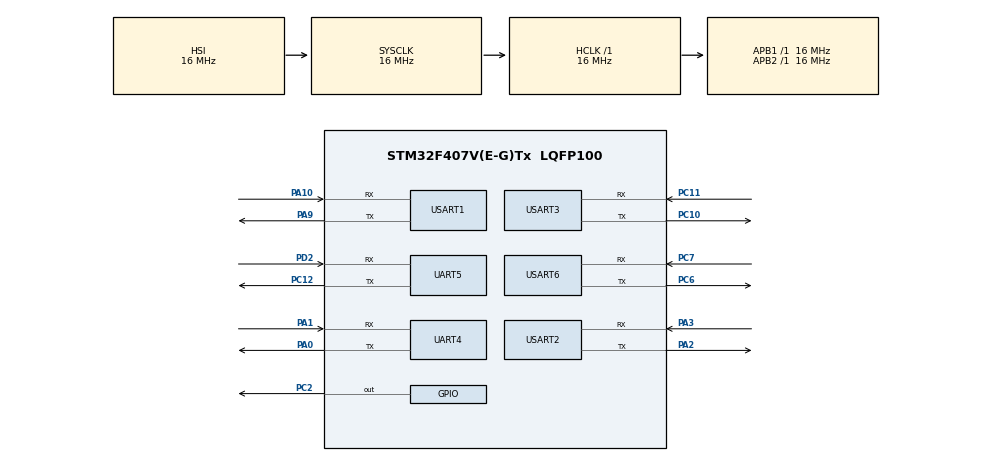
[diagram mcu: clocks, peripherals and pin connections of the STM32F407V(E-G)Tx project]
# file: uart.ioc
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Mcu.Family=STM32F4
RCC.CortexFreq_Value=16000000
PA10.Mode=Asynchronous
PC11.Signal=USART3_RX
PC10.Signal=USART3_TX
PC12.Signal=UART5_TX
PC2.Signal=GPIO_Output
PC6.Signal=USART6_TX
PC10.Mode=Asynchronous
UART5.VirtualMode=Asynchronous
UART4.VirtualMode=Asynchronous
ProjectManager.StackSize=0x400
PA0-WKUP.Signal=UART4_TX
PA0-WKUP.Mode=Asynchronous
PA3.Mode=Asynchronous
PA9.Mode=Asynchronous
ProjectManager.TargetToolchain=STM32CubeIDE
PC6.Mode=Asynchronous
PA9.Signal=USART1_TX
PC7.Signal=USART6_RX
RCC.LSE_VALUE=32768
PA1.Signal=UART4_RX
RCC.AHBFreq_Value=16000000
PD2.Mode=Asynchronous
RCC.HSE_VALUE=25000000
PC12.Mode=Asynchronous
board=custom
RCC.VCOOutputFreq_Value=192000000
RCC.APB2Freq_Value=16000000
PA1.Mode=Asynchronous
Mcu.Name=STM32F407V(E-G)Tx
PA2.Signal=USART2_TX
RCC.SYSCLKFreq_VALUE=16000000
Mcu.Package=LQFP100
USART2.VirtualMode=VM_ASYNC
USART3.VirtualMode=VM_ASYNC
USART6.VirtualMode=VM_ASYNC
USART1.VirtualMode=VM_ASYNC
PA10.Signal=USART1_RX
ProjectManager.HeapSize=0x200
PC11.Mode=Asynchronous
RCC.HSI_VALUE=16000000
NVIC.PriorityGroup=NVIC_PRIORITYGROUP_4
PA2.Mode=Asynchronous
PC7.Mode=Asynchronous
PD2.Signal=UART5_RX
RCC.APB1Freq_Value=16000000
PA3.Signal=USART2_RX

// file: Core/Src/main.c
/* USER CODE BEGIN Header */
/**
  ******************************************************************************
  * @file           : main.c
  * @brief          : Main program body
  ******************************************************************************
  * @attention
  *
  * <h2><center>&copy; Copyright (c) 2024 STMicroelectronics.
  * All rights reserved.</center></h2>
  *
  * This software component is licensed by ST under BSD 3-Clause license,
  * the "License"; You may not use this file except in compliance with the
  * License. You may obtain a copy of the License at:
  *                        opensource.org/licenses/BSD-3-Clause
  *
  ******************************************************************************
  */
/* USER CODE END Header */
#include "main.h"

UART_HandleTypeDef huart4;
UART_HandleTypeDef huart5;
UART_HandleTypeDef huart1;
UART_HandleTypeDef huart2;
UART_HandleTypeDef huart3;
UART_HandleTypeDef huart6;

/* USER CODE BEGIN PV */

uint8_t tx_buffer[8]="Aditya\r\n";

/* USER CODE END PV */

void SystemClock_Config(void);
static void MX_GPIO_Init(void);
static void MX_UART5_Init(void);
static void MX_UART4_Init(void);
static void MX_USART1_UART_Init(void);
static void MX_USART2_UART_Init(void);
static void MX_USART3_UART_Init(void);
static void MX_USART6_UART_Init(void);

int main(void)
{

  /* MCU Configuration--------------------------------------------------------*/

  /* Reset of all peripherals, Initializes the Flash interface and the Systick. */
  HAL_Init();

  /* Configure the system clock */
  SystemClock_Config();

  /* Initialize all configured peripherals */
  MX_GPIO_Init();
  MX_UART5_Init();
  MX_UART4_Init();
  MX_USART1_UART_Init();
  MX_USART2_UART_Init();
  MX_USART3_UART_Init();
  MX_USART6_UART_Init();

  /* Infinite loop */
  /* USER CODE BEGIN WHILE */
  while (1)
  {
	  HAL_UART_Transmit(&huart1, tx_buffer, 8 ,5);
	  HAL_UART_Transmit(&huart2, tx_buffer, 8 ,5);
	  HAL_UART_Transmit(&huart3, tx_buffer, 8 ,5);
	  HAL_UART_Transmit(&huart4, tx_buffer, 8 ,5);
	  HAL_UART_Transmit(&huart5, tx_buffer, 8 ,5);
	  HAL_UART_Transmit(&huart6, tx_buffer, 8 ,5);
	  HAL_Delay(1000);
    /* USER CODE END WHILE */

  }
}

void SystemClock_Config(void)
{
  RCC_OscInitTypeDef RCC_OscInitStruct = {0};
  RCC_ClkInitTypeDef RCC_ClkInitStruct = {0};

  /** Configure the main internal regulator output voltage
  */
  __HAL_RCC_PWR_CLK_ENABLE();
  __HAL_PWR_VOLTAGESCALING_CONFIG(PWR_REGULATOR_VOLTAGE_SCALE1);
  /** Initializes the RCC Oscillators according to the specified parameters
  * in the RCC_OscInitTypeDef structure.
  */
  RCC_OscInitStruct.OscillatorType = RCC_OSCILLATORTYPE_HSI;
  RCC_OscInitStruct.HSIState = RCC_HSI_ON;
  RCC_OscInitStruct.HSICalibrationValue = RCC_HSICALIBRATION_DEFAULT;
  RCC_OscInitStruct.PLL.PLLState = RCC_PLL_NONE;
  if (HAL_RCC_OscConfig(&RCC_OscInitStruct) != HAL_OK)
  {
    Error_Handler();
  }
  /** Initializes the CPU, AHB and APB buses clocks
  */
  RCC_ClkInitStruct.ClockType = RCC_CLOCKTYPE_HCLK|RCC_CLOCKTYPE_SYSCLK
                              |RCC_CLOCKTYPE_PCLK1|RCC_CLOCKTYPE_PCLK2;
  RCC_ClkInitStruct.SYSCLKSource = RCC_SYSCLKSOURCE_HSI;
  RCC_ClkInitStruct.AHBCLKDivider = RCC_SYSCLK_DIV1;
  RCC_ClkInitStruct.APB1CLKDivider = RCC_HCLK_DIV1;
  RCC_ClkInitStruct.APB2CLKDivider = RCC_HCLK_DIV1;

  if (HAL_RCC_ClockConfig(&RCC_ClkInitStruct, FLASH_LATENCY_0) != HAL_OK)
  {
    Error_Handler();
  }
}

static void MX_UART4_Init(void)
{

  huart4.Instance = UART4;
  huart4.Init.BaudRate = 115200;
  huart4.Init.WordLength = UART_WORDLENGTH_8B;
  huart4.Init.StopBits = UART_STOPBITS_1;
  huart4.Init.Parity = UART_PARITY_NONE;
  huart4.Init.Mode = UART_MODE_TX_RX;
  huart4.Init.HwFlowCtl = UART_HWCONTROL_NONE;
  huart4.Init.OverSampling = UART_OVERSAMPLING_16;
  if (HAL_UART_Init(&huart4) != HAL_OK)
  {
    Error_Handler();
  }

}

static void MX_UART5_Init(void)
{

  huart5.Instance = UART5;
  huart5.Init.BaudRate = 115200;
  huart5.Init.WordLength = UART_WORDLENGTH_8B;
  huart5.Init.StopBits = UART_STOPBITS_1;
  huart5.Init.Parity = UART_PARITY_NONE;
  huart5.Init.Mode = UART_MODE_TX_RX;
  huart5.Init.HwFlowCtl = UART_HWCONTROL_NONE;
  huart5.Init.OverSampling = UART_OVERSAMPLING_16;
  if (HAL_UART_Init(&huart5) != HAL_OK)
  {
    Error_Handler();
  }

}

static void MX_USART1_UART_Init(void)
{

  huart1.Instance = USART1;
  huart1.Init.BaudRate = 115200;
  huart1.Init.WordLength = UART_WORDLENGTH_8B;
  huart1.Init.StopBits = UART_STOPBITS_1;
  huart1.Init.Parity = UART_PARITY_NONE;
  huart1.Init.Mode = UART_MODE_TX_RX;
  huart1.Init.HwFlowCtl = UART_HWCONTROL_NONE;
  huart1.Init.OverSampling = UART_OVERSAMPLING_16;
  if (HAL_UART_Init(&huart1) != HAL_OK)
  {
    Error_Handler();
  }

}

static void MX_USART2_UART_Init(void)
{

  huart2.Instance = USART2;
  huart2.Init.BaudRate = 115200;
  huart2.Init.WordLength = UART_WORDLENGTH_8B;
  huart2.Init.StopBits = UART_STOPBITS_1;
  huart2.Init.Parity = UART_PARITY_NONE;
  huart2.Init.Mode = UART_MODE_TX_RX;
  huart2.Init.HwFlowCtl = UART_HWCONTROL_NONE;
  huart2.Init.OverSampling = UART_OVERSAMPLING_16;
  if (HAL_UART_Init(&huart2) != HAL_OK)
  {
    Error_Handler();
  }

}

static void MX_USART3_UART_Init(void)
{

  huart3.Instance = USART3;
  huart3.Init.BaudRate = 115200;
  huart3.Init.WordLength = UART_WORDLENGTH_8B;
  huart3.Init.StopBits = UART_STOPBITS_1;
  huart3.Init.Parity = UART_PARITY_NONE;
  huart3.Init.Mode = UART_MODE_TX_RX;
  huart3.Init.HwFlowCtl = UART_HWCONTROL_NONE;
  huart3.Init.OverSampling = UART_OVERSAMPLING_16;
  if (HAL_UART_Init(&huart3) != HAL_OK)
  {
    Error_Handler();
  }

}

static void MX_USART6_UART_Init(void)
{

  huart6.Instance = USART6;
  huart6.Init.BaudRate = 115200;
  huart6.Init.WordLength = UART_WORDLENGTH_8B;
  huart6.Init.StopBits = UART_STOPBITS_1;
  huart6.Init.Parity = UART_PARITY_NONE;
  huart6.Init.Mode = UART_MODE_TX_RX;
  huart6.Init.HwFlowCtl = UART_HWCONTROL_NONE;
  huart6.Init.OverSampling = UART_OVERSAMPLING_16;
  if (HAL_UART_Init(&huart6) != HAL_OK)
  {
    Error_Handler();
  }

}

static void MX_GPIO_Init(void)
{
  GPIO_InitTypeDef GPIO_InitStruct = {0};

  /* GPIO Ports Clock Enable */
  __HAL_RCC_GPIOC_CLK_ENABLE();
  __HAL_RCC_GPIOA_CLK_ENABLE();
  __HAL_RCC_GPIOD_CLK_ENABLE();

  /*Configure GPIO pin Output Level */
  HAL_GPIO_WritePin(GPIOC, GPIO_PIN_2, GPIO_PIN_RESET);

  /*Configure GPIO pin : PC2 */
  GPIO_InitStruct.Pin = GPIO_PIN_2;
  GPIO_InitStruct.Mode = GPIO_MODE_OUTPUT_PP;
  GPIO_InitStruct.Pull = GPIO_NOPULL;
  GPIO_InitStruct.Speed = GPIO_SPEED_FREQ_LOW;
  HAL_GPIO_Init(GPIOC, &GPIO_InitStruct);

}

void Error_Handler(void)
{
  __disable_irq();
  while (1)
  {
  }
}

/************************ (C) COPYRIGHT STMicroelectronics *****END OF FILE****/
